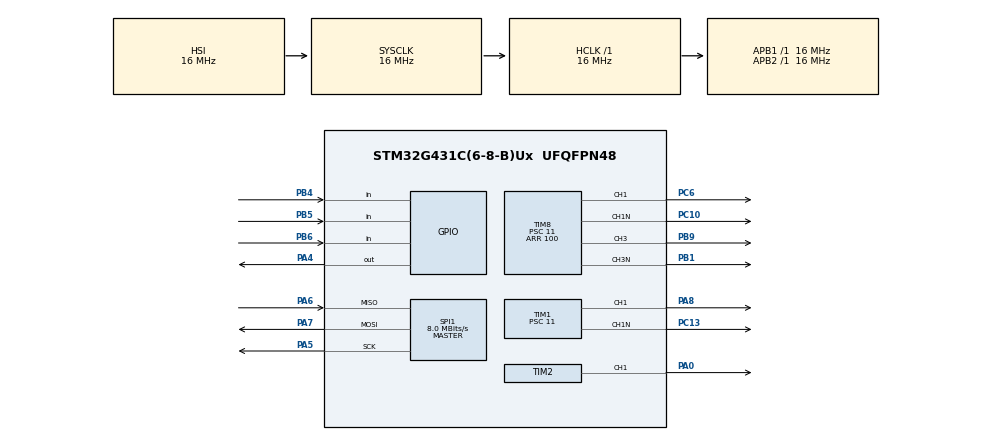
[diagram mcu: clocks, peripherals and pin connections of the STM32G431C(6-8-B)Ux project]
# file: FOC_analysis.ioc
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Mcu.Family=STM32G4
Mcu.Name=STM32G431C(6-8-B)Ux
Mcu.Package=UFQFPN48
NVIC.PriorityGroup=NVIC_PRIORITYGROUP_4
NVIC.TIM1_UP_TIM16_IRQn=true\:0\:0\:false\:false\:true\:true\:true\:true
NVIC.TIM2_IRQn=true\:0\:0\:false\:false\:true\:true\:true\:true
NVIC.TIM8_UP_IRQn=true\:0\:0\:false\:false\:true\:true\:true\:true
PA0.Signal=S_TIM2_CH1
PA13.Mode=Serial_Wire
PA13.Signal=SYS_JTMS-SWDIO
PA14.Mode=Serial_Wire
PA14.Signal=SYS_JTCK-SWCLK
PA4.Signal=GPIO_Output
PA5.Mode=Full_Duplex_Master
PA5.Signal=SPI1_SCK
PA6.Mode=Full_Duplex_Master
PA6.Signal=SPI1_MISO
PA7.Mode=Full_Duplex_Master
PA7.Signal=SPI1_MOSI
PA8.Signal=S_TIM1_CH1
PB1.Mode=PWM Generation3 CH3 CH3N
PB1.Signal=TIM8_CH3N
PB4.Signal=GPIO_Input
PB5.Signal=GPIO_Input
PB6.Signal=GPIO_Input
PB9.Signal=S_TIM8_CH3
PC10.Mode=PWM Generation1 CH1 CH1N
PC10.Signal=TIM8_CH1N
PC13.Mode=PWM Generation1 CH1 CH1N
PC13.Signal=TIM1_CH1N
PC6.Signal=S_TIM8_CH1
ProjectManager.HeapSize=0x200
ProjectManager.StackSize=0x400
ProjectManager.TargetToolchain=MDK-ARM V5.32
RCC.AHBFreq_Value=16000000
RCC.APB1Freq_Value=16000000
RCC.APB1TimFreq_Value=16000000
RCC.APB2Freq_Value=16000000
RCC.APB2TimFreq_Value=16000000
RCC.CortexFreq_Value=16000000
RCC.EXTERNAL_CLOCK_VALUE=12288000
RCC.HCLKFreq_Value=16000000
RCC.HSE_VALUE=8000000
RCC.HSI48_VALUE=48000000
RCC.HSI_VALUE=16000000
RCC.LSE_VALUE=32768
RCC.SYSCLKFreq_VALUE=16000000
RCC.USBFreq_Value=64000000
RCC.VCOOutputFreq_Value=128000000
SH.S_TIM1_CH1.0=TIM1_CH1,PWM Generation1 CH1 CH1N
SH.S_TIM2_CH1.0=TIM2_CH1,PWM Generation1 CH1
SH.S_TIM8_CH1.0=TIM8_CH1,PWM Generation1 CH1 CH1N
SH.S_TIM8_CH3.0=TIM8_CH3,PWM Generation3 CH3 CH3N
SPI1.CalculateBaudRate=8.0 MBits/s
SPI1.Direction=SPI_DIRECTION_2LINES
SPI1.Mode=SPI_MODE_MASTER
SPI1.VirtualType=VM_MASTER
TIM1.Channel-PWM\ Generation1\ CH1\ CH1N=TIM_CHANNEL_1
TIM1.PeriodNoDither=100
TIM1.Prescaler=11
TIM2.Channel-PWM\ Generation1\ CH1=TIM_CHANNEL_1
TIM2.PeriodNoDither=4
TIM2.Prescaler=23999
TIM2.PulseNoDither_1=4
TIM8.Channel-PWM\ Generation1\ CH1\ CH1N=TIM_CHANNEL_1
TIM8.Channel-PWM\ Generation3\ CH3\ CH3N=TIM_CHANNEL_3
TIM8.PeriodNoDither=100
TIM8.Prescaler=11
VP_SYS_VS_DBSignals.Mode=DisableDeadBatterySignals
board=custom

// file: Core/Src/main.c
/* USER CODE BEGIN Header */
/**
  ******************************************************************************
  * @file           : main.c
  * @brief          : Main program body
  ******************************************************************************
  * @attention
  *
  * Copyright (c) 2025 STMicroelectronics.
  * All rights reserved.
  *
  * This software is licensed under terms that can be found in the LICENSE file
  * in the root directory of this software component.
  * If no LICENSE file comes with this software, it is provided AS-IS.
  *
  ******************************************************************************
  */
/* USER CODE END Header */
#include "main.h"
#include "foc_cal.h"

float id,iq, theta;
float ia,ib,ic;

SPI_HandleTypeDef hspi1;

TIM_HandleTypeDef htim1;
TIM_HandleTypeDef htim2;
TIM_HandleTypeDef htim8;

void SystemClock_Config(void);
static void MX_GPIO_Init(void);
static void MX_SPI1_Init(void);
static void MX_TIM1_Init(void);
static void MX_TIM8_Init(void);
static void MX_TIM2_Init(void);
/* USER CODE BEGIN PFP */
void process(float ia, float ib, float ic, float theta, float *id, float *iq,float v_ref,float fb)
{
    float v, v_d, v_q;
    float va, vb, vc;

    iabc_2_idq(ia, ib, ic, theta, id, iq);

    v = PI_controller(v_ref, fb, 0.9, 1.2, 0.000005);
    v_d = PI_controller(0, *id, 0.72, 0.85, 0.000005);
    v_q = PI_controller(v, *iq, 0.72, 0.85, 0.000005);

    idq_2_iabc(theta, v_d, v_q, &va, &vb, &vc);

    pwm(va, vb, vc);
}

/* USER CODE END PFP */

int main(void)
{

  /* MCU Configuration--------------------------------------------------------*/

  /* Reset of all peripherals, Initializes the Flash interface and the Systick. */
  HAL_Init();

  /* Configure the system clock */
  SystemClock_Config();

  /* Initialize all configured peripherals */
  MX_GPIO_Init();
  MX_SPI1_Init();
  MX_TIM1_Init();
  MX_TIM8_Init();
  MX_TIM2_Init();
  /* USER CODE BEGIN 2 */

	// Khoi tao timer
	HAL_TIM_PWM_Start(&htim1, TIM_CHANNEL_1);
	HAL_TIM_PWM_Start(&htim8, TIM_CHANNEL_1);
	HAL_TIM_PWM_Start(&htim8, TIM_CHANNEL_3);
	HAL_TIM_Base_Start_IT(&htim2);
  /* USER CODE END 2 */

  /* Infinite loop */
  while (1)
  {

  }
}

void SystemClock_Config(void)
{
  RCC_OscInitTypeDef RCC_OscInitStruct = {0};
  RCC_ClkInitTypeDef RCC_ClkInitStruct = {0};

  /** Configure the main internal regulator output voltage
  */
  HAL_PWREx_ControlVoltageScaling(PWR_REGULATOR_VOLTAGE_SCALE1);

  /** Initializes the RCC Oscillators according to the specified parameters
  * in the RCC_OscInitTypeDef structure.
  */
  RCC_OscInitStruct.OscillatorType = RCC_OSCILLATORTYPE_HSI;
  RCC_OscInitStruct.HSIState = RCC_HSI_ON;
  RCC_OscInitStruct.HSICalibrationValue = RCC_HSICALIBRATION_DEFAULT;
  RCC_OscInitStruct.PLL.PLLState = RCC_PLL_NONE;
  if (HAL_RCC_OscConfig(&RCC_OscInitStruct) != HAL_OK)
  {
    Error_Handler();
  }

  /** Initializes the CPU, AHB and APB buses clocks
  */
  RCC_ClkInitStruct.ClockType = RCC_CLOCKTYPE_HCLK|RCC_CLOCKTYPE_SYSCLK
                              |RCC_CLOCKTYPE_PCLK1|RCC_CLOCKTYPE_PCLK2;
  RCC_ClkInitStruct.SYSCLKSource = RCC_SYSCLKSOURCE_HSI;
  RCC_ClkInitStruct.AHBCLKDivider = RCC_SYSCLK_DIV1;
  RCC_ClkInitStruct.APB1CLKDivider = RCC_HCLK_DIV1;
  RCC_ClkInitStruct.APB2CLKDivider = RCC_HCLK_DIV1;

  if (HAL_RCC_ClockConfig(&RCC_ClkInitStruct, FLASH_LATENCY_0) != HAL_OK)
  {
    Error_Handler();
  }
}

static void MX_SPI1_Init(void)
{

  /* SPI1 parameter configuration*/
  hspi1.Instance = SPI1;
  hspi1.Init.Mode = SPI_MODE_MASTER;
  hspi1.Init.Direction = SPI_DIRECTION_2LINES;
  hspi1.Init.DataSize = SPI_DATASIZE_4BIT;
  hspi1.Init.CLKPolarity = SPI_POLARITY_LOW;
  hspi1.Init.CLKPhase = SPI_PHASE_1EDGE;
  hspi1.Init.NSS = SPI_NSS_SOFT;
  hspi1.Init.BaudRatePrescaler = SPI_BAUDRATEPRESCALER_2;
  hspi1.Init.FirstBit = SPI_FIRSTBIT_MSB;
  hspi1.Init.TIMode = SPI_TIMODE_DISABLE;
  hspi1.Init.CRCCalculation = SPI_CRCCALCULATION_DISABLE;
  hspi1.Init.CRCPolynomial = 7;
  hspi1.Init.CRCLength = SPI_CRC_LENGTH_DATASIZE;
  hspi1.Init.NSSPMode = SPI_NSS_PULSE_ENABLE;
  if (HAL_SPI_Init(&hspi1) != HAL_OK)
  {
    Error_Handler();
  }

}

static void MX_TIM1_Init(void)
{

  TIM_MasterConfigTypeDef sMasterConfig = {0};
  TIM_OC_InitTypeDef sConfigOC = {0};
  TIM_BreakDeadTimeConfigTypeDef sBreakDeadTimeConfig = {0};

  htim1.Instance = TIM1;
  htim1.Init.Prescaler = 11;
  htim1.Init.CounterMode = TIM_COUNTERMODE_UP;
  htim1.Init.Period = 99;
  htim1.Init.ClockDivision = TIM_CLOCKDIVISION_DIV1;
  htim1.Init.RepetitionCounter = 0;
  htim1.Init.AutoReloadPreload = TIM_AUTORELOAD_PRELOAD_DISABLE;
  if (HAL_TIM_PWM_Init(&htim1) != HAL_OK)
  {
    Error_Handler();
  }
  sMasterConfig.MasterOutputTrigger = TIM_TRGO_RESET;
  sMasterConfig.MasterOutputTrigger2 = TIM_TRGO2_RESET;
  sMasterConfig.MasterSlaveMode = TIM_MASTERSLAVEMODE_DISABLE;
  if (HAL_TIMEx_MasterConfigSynchronization(&htim1, &sMasterConfig) != HAL_OK)
  {
    Error_Handler();
  }
  sConfigOC.OCMode = TIM_OCMODE_PWM1;
  sConfigOC.Pulse = 0;
  sConfigOC.OCPolarity = TIM_OCPOLARITY_HIGH;
  sConfigOC.OCNPolarity = TIM_OCNPOLARITY_HIGH;
  sConfigOC.OCFastMode = TIM_OCFAST_DISABLE;
  sConfigOC.OCIdleState = TIM_OCIDLESTATE_RESET;
  sConfigOC.OCNIdleState = TIM_OCNIDLESTATE_RESET;
  if (HAL_TIM_PWM_ConfigChannel(&htim1, &sConfigOC, TIM_CHANNEL_1) != HAL_OK)
  {
    Error_Handler();
  }
  sBreakDeadTimeConfig.OffStateRunMode = TIM_OSSR_DISABLE;
  sBreakDeadTimeConfig.OffStateIDLEMode = TIM_OSSI_DISABLE;
  sBreakDeadTimeConfig.LockLevel = TIM_LOCKLEVEL_OFF;
  sBreakDeadTimeConfig.DeadTime = 0;
  sBreakDeadTimeConfig.BreakState = TIM_BREAK_DISABLE;
  sBreakDeadTimeConfig.BreakPolarity = TIM_BREAKPOLARITY_HIGH;
  sBreakDeadTimeConfig.BreakFilter = 0;
  sBreakDeadTimeConfig.BreakAFMode = TIM_BREAK_AFMODE_INPUT;
  sBreakDeadTimeConfig.Break2State = TIM_BREAK2_DISABLE;
  sBreakDeadTimeConfig.Break2Polarity = TIM_BREAK2POLARITY_HIGH;
  sBreakDeadTimeConfig.Break2Filter = 0;
  sBreakDeadTimeConfig.Break2AFMode = TIM_BREAK_AFMODE_INPUT;
  sBreakDeadTimeConfig.AutomaticOutput = TIM_AUTOMATICOUTPUT_DISABLE;
  if (HAL_TIMEx_ConfigBreakDeadTime(&htim1, &sBreakDeadTimeConfig) != HAL_OK)
  {
    Error_Handler();
  }
  HAL_TIM_MspPostInit(&htim1);

}

static void MX_TIM2_Init(void)
{

  TIM_MasterConfigTypeDef sMasterConfig = {0};
  TIM_OC_InitTypeDef sConfigOC = {0};

  htim2.Instance = TIM2;
  htim2.Init.Prescaler = 399;
  htim2.Init.CounterMode = TIM_COUNTERMODE_UP;
  htim2.Init.Period = 99;
  htim2.Init.ClockDivision = TIM_CLOCKDIVISION_DIV1;
  htim2.Init.AutoReloadPreload = TIM_AUTORELOAD_PRELOAD_DISABLE;
  if (HAL_TIM_PWM_Init(&htim2) != HAL_OK)
  {
    Error_Handler();
  }
  sMasterConfig.MasterOutputTrigger = TIM_TRGO_RESET;
  sMasterConfig.MasterSlaveMode = TIM_MASTERSLAVEMODE_DISABLE;
  if (HAL_TIMEx_MasterConfigSynchronization(&htim2, &sMasterConfig) != HAL_OK)
  {
    Error_Handler();
  }
  sConfigOC.OCMode = TIM_OCMODE_PWM1;
  sConfigOC.Pulse = 4;
  sConfigOC.OCPolarity = TIM_OCPOLARITY_HIGH;
  sConfigOC.OCFastMode = TIM_OCFAST_DISABLE;
  if (HAL_TIM_PWM_ConfigChannel(&htim2, &sConfigOC, TIM_CHANNEL_1) != HAL_OK)
  {
    Error_Handler();
  }
  HAL_TIM_MspPostInit(&htim2);

}

static void MX_TIM8_Init(void)
{

  TIM_MasterConfigTypeDef sMasterConfig = {0};
  TIM_OC_InitTypeDef sConfigOC = {0};
  TIM_BreakDeadTimeConfigTypeDef sBreakDeadTimeConfig = {0};

  htim8.Instance = TIM8;
  htim8.Init.Prescaler = 11;
  htim8.Init.CounterMode = TIM_COUNTERMODE_UP;
  htim8.Init.Period = 99;
  htim8.Init.ClockDivision = TIM_CLOCKDIVISION_DIV1;
  htim8.Init.RepetitionCounter = 0;
  htim8.Init.AutoReloadPreload = TIM_AUTORELOAD_PRELOAD_DISABLE;
  if (HAL_TIM_PWM_Init(&htim8) != HAL_OK)
  {
    Error_Handler();
  }
  sMasterConfig.MasterOutputTrigger = TIM_TRGO_RESET;
  sMasterConfig.MasterOutputTrigger2 = TIM_TRGO2_RESET;
  sMasterConfig.MasterSlaveMode = TIM_MASTERSLAVEMODE_DISABLE;
  if (HAL_TIMEx_MasterConfigSynchronization(&htim8, &sMasterConfig) != HAL_OK)
  {
    Error_Handler();
  }
  sConfigOC.OCMode = TIM_OCMODE_PWM1;
  sConfigOC.Pulse = 0;
  sConfigOC.OCPolarity = TIM_OCPOLARITY_HIGH;
  sConfigOC.OCNPolarity = TIM_OCNPOLARITY_HIGH;
  sConfigOC.OCFastMode = TIM_OCFAST_DISABLE;
  sConfigOC.OCIdleState = TIM_OCIDLESTATE_RESET;
  sConfigOC.OCNIdleState = TIM_OCNIDLESTATE_RESET;
  if (HAL_TIM_PWM_ConfigChannel(&htim8, &sConfigOC, TIM_CHANNEL_1) != HAL_OK)
  {
    Error_Handler();
  }
  if (HAL_TIM_PWM_ConfigChannel(&htim8, &sConfigOC, TIM_CHANNEL_3) != HAL_OK)
  {
    Error_Handler();
  }
  sBreakDeadTimeConfig.OffStateRunMode = TIM_OSSR_DISABLE;
  sBreakDeadTimeConfig.OffStateIDLEMode = TIM_OSSI_DISABLE;
  sBreakDeadTimeConfig.LockLevel = TIM_LOCKLEVEL_OFF;
  sBreakDeadTimeConfig.DeadTime = 0;
  sBreakDeadTimeConfig.BreakState = TIM_BREAK_DISABLE;
  sBreakDeadTimeConfig.BreakPolarity = TIM_BREAKPOLARITY_HIGH;
  sBreakDeadTimeConfig.BreakFilter = 0;
  sBreakDeadTimeConfig.BreakAFMode = TIM_BREAK_AFMODE_INPUT;
  sBreakDeadTimeConfig.Break2State = TIM_BREAK2_DISABLE;
  sBreakDeadTimeConfig.Break2Polarity = TIM_BREAK2POLARITY_HIGH;
  sBreakDeadTimeConfig.Break2Filter = 0;
  sBreakDeadTimeConfig.Break2AFMode = TIM_BREAK_AFMODE_INPUT;
  sBreakDeadTimeConfig.AutomaticOutput = TIM_AUTOMATICOUTPUT_DISABLE;
  if (HAL_TIMEx_ConfigBreakDeadTime(&htim8, &sBreakDeadTimeConfig) != HAL_OK)
  {
    Error_Handler();
  }
  HAL_TIM_MspPostInit(&htim8);

}

static void MX_GPIO_Init(void)
{
  GPIO_InitTypeDef GPIO_InitStruct = {0};

  /* GPIO Ports Clock Enable */
  __HAL_RCC_GPIOC_CLK_ENABLE();
  __HAL_RCC_GPIOA_CLK_ENABLE();
  __HAL_RCC_GPIOB_CLK_ENABLE();

  /*Configure GPIO pin Output Level */
  HAL_GPIO_WritePin(GPIOA, GPIO_PIN_4, GPIO_PIN_RESET);

  /*Configure GPIO pin : PA4 */
  GPIO_InitStruct.Pin = GPIO_PIN_4;
  GPIO_InitStruct.Mode = GPIO_MODE_OUTPUT_PP;
  GPIO_InitStruct.Pull = GPIO_NOPULL;
  GPIO_InitStruct.Speed = GPIO_SPEED_FREQ_LOW;
  HAL_GPIO_Init(GPIOA, &GPIO_InitStruct);

  /*Configure GPIO pins : PB4 PB5 PB6 */
  GPIO_InitStruct.Pin = GPIO_PIN_4|GPIO_PIN_5|GPIO_PIN_6;
  GPIO_InitStruct.Mode = GPIO_MODE_INPUT;
  GPIO_InitStruct.Pull = GPIO_NOPULL;
  HAL_GPIO_Init(GPIOB, &GPIO_InitStruct);

}

void Error_Handler(void)
{
  __disable_irq();
  while (1)
  {
  }
}
